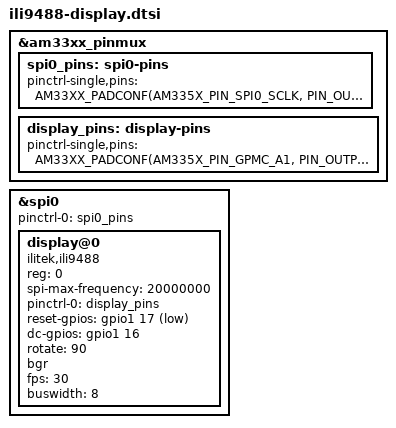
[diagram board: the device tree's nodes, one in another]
/*
 * Device Tree overlay for ILI9488 SPI Display on BeagleBone
 * Uses custom fb_ili9488 FBTFT driver
 *
 * Display Connections:
 *   VCC  -> P9.3 or P9.4 (3.3V)
 *   GND  -> P9.1 or P9.2 (GND)
 *   CS   -> P9.17 (SPI0_CS0)
 *   RST  -> P9.23 (GPIO1_17)
 *   DC   -> P9.15 (GPIO1_16)
 *   MOSI -> P9.18 (SPI0_D1)
 *   SCK  -> P9.22 (SPI0_SCLK)
 *   LED  -> 3.3V (always on)
 *   MISO -> P9.21 (SPI0_D0) - optional
 */

&am33xx_pinmux {
	spi0_pins: spi0-pins {
		pinctrl-single,pins = <
			AM33XX_PADCONF(AM335X_PIN_SPI0_SCLK, PIN_OUTPUT_PULLUP, MUX_MODE0)
			AM33XX_PADCONF(AM335X_PIN_SPI0_D0, PIN_INPUT_PULLUP, MUX_MODE0)
			AM33XX_PADCONF(AM335X_PIN_SPI0_D1, PIN_OUTPUT_PULLUP, MUX_MODE0)
			AM33XX_PADCONF(AM335X_PIN_SPI0_CS0, PIN_OUTPUT_PULLUP, MUX_MODE0)
		>;
	};

	display_pins: display-pins {
		pinctrl-single,pins = <
			AM33XX_PADCONF(AM335X_PIN_GPMC_A1, PIN_OUTPUT, MUX_MODE7)
			AM33XX_PADCONF(AM335X_PIN_GPMC_A0, PIN_OUTPUT, MUX_MODE7)
		>;
	};
};

&spi0 {
	status = "okay";
	pinctrl-names = "default";
	pinctrl-0 = <&spi0_pins>;

	display@0 {
		compatible = "ilitek,ili9488";
		reg = <0>;
		spi-max-frequency = <20000000>;

		pinctrl-names = "default";
		pinctrl-0 = <&display_pins>;

		reset-gpios = <&gpio1 17 GPIO_ACTIVE_LOW>;
		dc-gpios = <&gpio1 16 GPIO_ACTIVE_HIGH>;

		rotate = <90>;
		bgr;
		fps = <30>;
		buswidth = <8>;
	};
};
